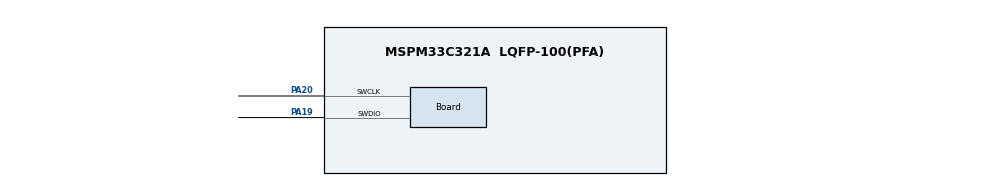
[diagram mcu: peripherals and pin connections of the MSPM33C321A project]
//@cliArgs --device "MSPM33C321A" --package "LQFP-100(PFA)" --part "Default"
//@v2CliArgs --device "MSPM33C321A" --package "LQFP-100(PFA)"
// @cliArgs --board /ti/boards/LP_MSPM33C321A --rtos nortos

/**
 * Import the modules used in this configuration.
 */
const HSADC         = scripting.addModule("/ti/driverlib/HSADC", {}, false);
const HSADC1        = HSADC.addInstance();
const HSADC2        = HSADC.addInstance();
const ProjectConfig = scripting.addModule("/ti/project_config/ProjectConfig");

/**
 * Write custom configuration values to the imported modules.
 */

const Board                       = scripting.addModule("/ti/driverlib/Board", {}, false);
Board.peripheral.$assign          = "DEBUGSS";
Board.peripheral.swclkPin.$assign = "PA20";
Board.peripheral.swdioPin.$assign = "PA19";

HSADC1.$name              = "HSADC0";
HSADC1.enabledSOCs        = ["ADC_SOC_NUMBER0","ADC_SOC_NUMBER1","ADC_SOC_NUMBER10","ADC_SOC_NUMBER11","ADC_SOC_NUMBER12","ADC_SOC_NUMBER13","ADC_SOC_NUMBER14","ADC_SOC_NUMBER15","ADC_SOC_NUMBER2","ADC_SOC_NUMBER3","ADC_SOC_NUMBER4","ADC_SOC_NUMBER5","ADC_SOC_NUMBER6","ADC_SOC_NUMBER7","ADC_SOC_NUMBER8","ADC_SOC_NUMBER9"];
HSADC1.enabledSEQs        = ["ADC_SEQ_NUMBER1","ADC_SEQ_NUMBER2","ADC_SEQ_NUMBER3","ADC_SEQ_NUMBER4"];
HSADC1.seqEndSOC          = "ADC_SOC_NUMBER15";
HSADC1.seq1Enable         = true;
HSADC1.seq1SampleWindow   = 16;
HSADC1.seq2StartSOC       = "ADC_SOC_NUMBER4";
HSADC1.seq2Enable         = true;
HSADC1.seq2SampleWindow   = 16;
HSADC1.seq3StartSOC       = "ADC_SOC_NUMBER8";
HSADC1.seq3SampleWindow   = 16;
HSADC1.seq3Enable         = true;
HSADC1.seq4StartSOC       = "ADC_SOC_NUMBER12";
HSADC1.seq4Enable         = true;
HSADC1.seq4SampleWindow   = 16;
HSADC1.peripheral.$assign = "ADC0";

HSADC2.$name              = "HSADC1";
HSADC2.enabledSOCs        = ["ADC_SOC_NUMBER0","ADC_SOC_NUMBER1","ADC_SOC_NUMBER10","ADC_SOC_NUMBER11","ADC_SOC_NUMBER12","ADC_SOC_NUMBER13","ADC_SOC_NUMBER14","ADC_SOC_NUMBER15","ADC_SOC_NUMBER2","ADC_SOC_NUMBER3","ADC_SOC_NUMBER4","ADC_SOC_NUMBER5","ADC_SOC_NUMBER6","ADC_SOC_NUMBER7","ADC_SOC_NUMBER8","ADC_SOC_NUMBER9"];
HSADC2.enabledSEQs        = ["ADC_SEQ_NUMBER1","ADC_SEQ_NUMBER2","ADC_SEQ_NUMBER3","ADC_SEQ_NUMBER4"];
HSADC2.seqEndSOC          = "ADC_SOC_NUMBER15";
HSADC2.seq1Enable         = true;
HSADC2.seq1SampleWindow   = 16;
HSADC2.seq2StartSOC       = "ADC_SOC_NUMBER4";
HSADC2.seq2Enable         = true;
HSADC2.seq2SampleWindow   = 16;
HSADC2.seq3SampleWindow   = 16;
HSADC2.seq3Enable         = true;
HSADC2.seq3StartSOC       = "ADC_SOC_NUMBER8";
HSADC2.seq4StartSOC       = "ADC_SOC_NUMBER12";
HSADC2.seq4Enable         = true;
HSADC2.seq4SampleWindow   = 16;
HSADC2.peripheral.$assign = "ADC1";

const SYSCTL              = scripting.addModule("/ti/driverlib/SYSCTL", {}, false);
SYSCTL.peripheral.$assign = "SYSCTL";

ProjectConfig.genLinker          = true;
ProjectConfig.genStartup         = true;
ProjectConfig.genOpts            = true;
ProjectConfig.genLibs            = true;
ProjectConfig.migrationCondition = true;
